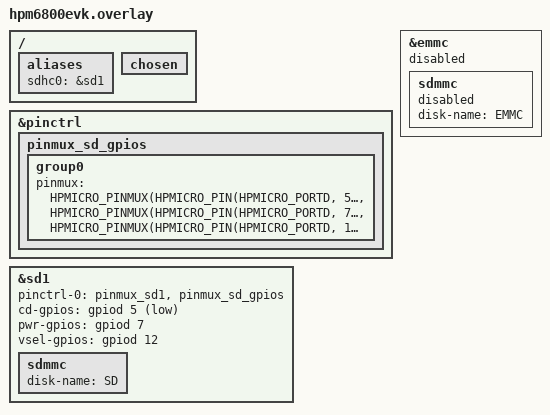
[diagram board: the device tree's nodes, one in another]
/*
* Copyright 2024-2026 HPMicro
* SPDX-License-Identifier: Apache-2.0
*/

/ {
	aliases {
		sdhc0 = &sd1;
	};

	chosen {
	};
};

&pinctrl {
	pinmux_sd_gpios: pinmux_sd_gpios {
		group0 {
			pinmux = <HPMICRO_PINMUX(HPMICRO_PIN(HPMICRO_PORTD, 5), IOC_TYPE_IOC, 0, 0)>,
				<HPMICRO_PINMUX(HPMICRO_PIN(HPMICRO_PORTD, 7), IOC_TYPE_IOC, 0, 0)>,
				<HPMICRO_PINMUX(HPMICRO_PIN(HPMICRO_PORTD, 12), IOC_TYPE_IOC, 0, 0)>;
		};
	};
};

&sd1 {
	status = "okay";
	pinctrl-0 = <&pinmux_sd1 &pinmux_sd_gpios>;
	cd-gpios = <&gpiod 5 ( GPIO_PULL_UP | GPIO_ACTIVE_LOW)>;
	pwr-gpios = <&gpiod 7 ( GPIO_PULL_UP | GPIO_ACTIVE_HIGH )>;
	vsel-gpios = <&gpiod 12 ( GPIO_PULL_UP)>;
	sdmmc {
		disk-name = "SD";
		status = "okay";
	};
};

&emmc {
	status = "disabled";
	sdmmc {
		disk-name = "EMMC";
		status = "disabled";
	};
};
